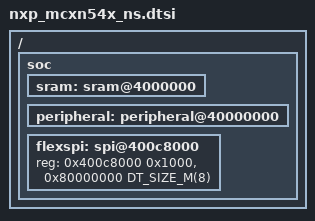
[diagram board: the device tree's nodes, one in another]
/*
 * Copyright 2025 Swiss Timing Ltd.
 *
 * SPDX-License-Identifier: Apache-2.0
 */

#include <mem.h>
#include <arm/armv8-m.dtsi>

/ {
	soc {
		sram: sram@4000000 {
			ranges = <0x4000000 0x4000000 0x20000000>;
		};

		peripheral: peripheral@40000000 {
			ranges = <0x0 0x40000000 0x10000000>;
		};

		flexspi: spi@400c8000 {
			reg = <0x400c8000 0x1000>, <0x80000000 DT_SIZE_M(8)>;
		};
	};
};

#include "nxp_mcxnx4x_common.dtsi"
